BO_ 213 BREAK_POSITION: 8 XXX
 SG_ BRAKE_POSITION : 0|12@1+ (1,0) [0|4095] "" XXX

BO_ 287 STEER_ANGLE_SENSOR: 5 XXX
 SG_ STEER_RACK_ANGLE : 0|16@1- (0.01,0) [-50|50] "deg" XXX
 SG_ STEER_TORQUE_MAG : 16|8@1+ (1,0) [0|255] "Nm" XXX

BO_ 482 NEW_MSG_1E2: 8 XXX
 SG_ STEER_ANGLE_2 : 24|16@1- (0.01,0) [0|65535] "" XXX

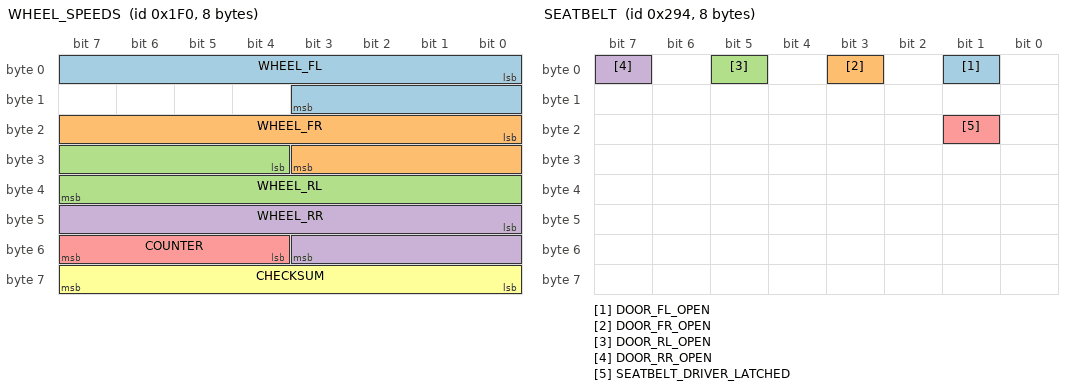
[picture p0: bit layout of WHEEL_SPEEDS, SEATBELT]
BO_ 496 WHEEL_SPEEDS: 8 XXX
 SG_ WHEEL_FL : 0|12@1+ (0.075,0) [0|4095] "" XXX
 SG_ WHEEL_FR : 16|12@1+ (0.075,0) [0|4095] "" XXX
 SG_ WHEEL_RL : 28|12@1+ (0.075,0) [0|31] "" XXX
 SG_ WHEEL_RR : 40|12@1+ (0.075,0) [0|8191] "" XXX
 SG_ COUNTER : 55|4@0+ (1,0) [0|15] "" XXX
 SG_ CHECKSUM : 56|8@1+ (1,0) [0|255] "" XXX

BO_ 537 BRAKE: 8 XXX
 SG_ BRAKE_PRESSED : 2|1@0+ (1,0) [0|1] "" XXX

BO_ 660 SEATBELT: 8 XXX
 SG_ DOOR_FL_OPEN : 1|1@0+ (1,0) [0|1] "" XXX
 SG_ DOOR_FR_OPEN : 3|1@0+ (1,0) [0|1] "" XXX
 SG_ DOOR_RL_OPEN : 5|1@0+ (1,0) [0|1] "" XXX
 SG_ DOOR_RR_OPEN : 7|1@0+ (1,0) [0|1] "" XXX
 SG_ SEATBELT_DRIVER_LATCHED : 17|1@0+ (1,0) [0|1] "" XXX

BO_ 663 NEW_MSG_297: 8 XXX

BO_ 790 ICC_STATE: 8 XXX
 SG_ ACC_ON : 27|1@0+ (1,0) [0|1] "" XXX
 SG_ ICC_ON : 28|1@0+ (1,0) [0|1] "" XXX

BO_ 860 GEAR_STATE: 8 XXX
 SG_ GEAR_STATE : 8|3@1+ (1,0) [0|7] "" XXX

BO_ 868 : 8 XXX

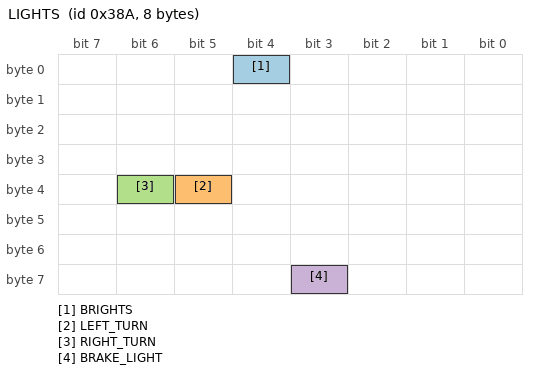
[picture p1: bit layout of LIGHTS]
BO_ 906 LIGHTS: 8 XXX
 SG_ BRIGHTS : 4|1@0+ (1,0) [0|1] "" XXX
 SG_ LEFT_TURN : 37|1@0+ (1,0) [0|1] "" XXX
 SG_ RIGHT_TURN : 38|1@0+ (1,0) [0|1] "" XXX
 SG_ BRAKE_LIGHT : 59|1@0+ (1,0) [0|1] "" XXX

BO_ 940 : 8 XXX

BO_ 1028 IGNITION: 8 XXX
 SG_ IGNITION_ON : 6|1@0+ (1,0) [0|1] "" XXX

BO_ 1093 maybe_ignition: 8 XXX

VAL_ 860 GEAR_STATE 1 "P" 2 "R" 3 "N" 4 "D" 0 "UNKNOWN" 5 "UNKNOWN" 6 "UNKNOWN" 7 "UNKNOWN";
